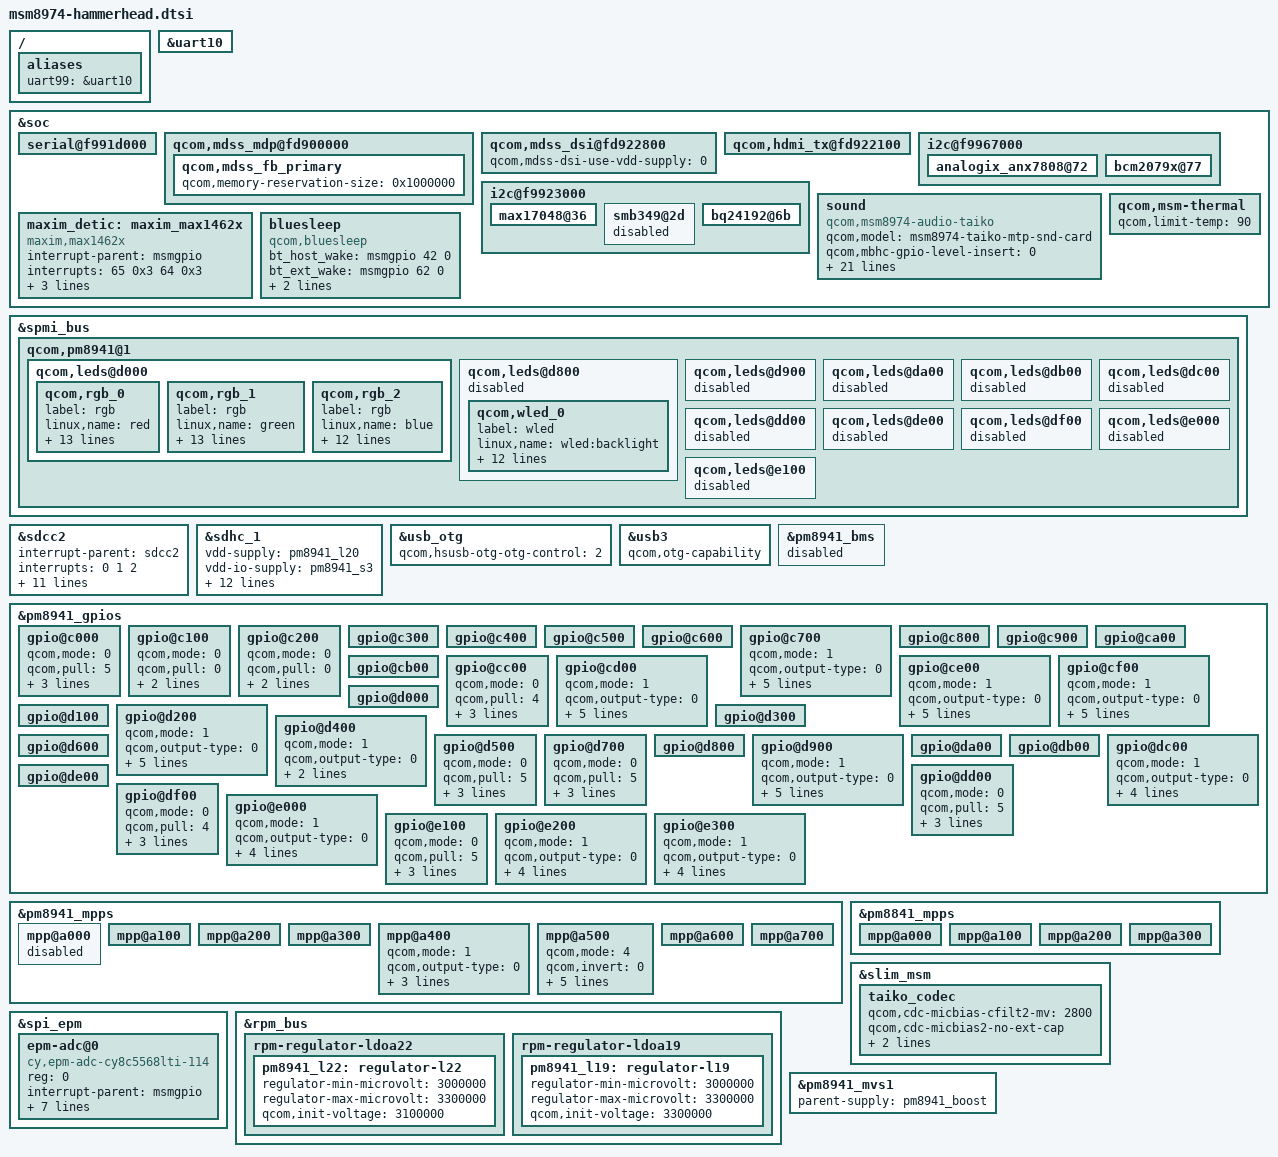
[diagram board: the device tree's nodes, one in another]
/* Copyright (c) 2012, Code Aurora Forum. All rights reserved.
 *
 * This program is free software; you can redistribute it and/or modify
 * it under the terms of the GNU General Public License version 2 and
 * only version 2 as published by the Free Software Foundation.
 *
 * This program is distributed in the hope that it will be useful,
 * but WITHOUT ANY WARRANTY; without even the implied warranty of
 * MERCHANTABILITY or FITNESS FOR A PARTICULAR PURPOSE.  See the
 * GNU General Public License for more details.
 */

/include/ "msm8974-hammerhead-panel.dtsi"
/include/ "msm8974-hammerhead-input.dtsi"
/include/ "msm8974-hammerhead-hdmi.dtsi"
/include/ "msm8974-hammerhead-usb.dtsi"
/include/ "msm8974-hammerhead-misc.dtsi"
/include/ "msm8974-hammerhead-pm.dtsi"
/include/ "msm8974-hammerhead-camera.dtsi"
/include/ "msm8974-hammerhead-nfc.dtsi"
/include/ "msm8974-hammerhead-regulator.dtsi"
/include/ "msm8974-hammerhead-sensor.dtsi"

/ {
	aliases {
		uart99 = &uart10;
	};
};

&uart10 {
	status = "ok";
};

&soc {
	serial@f991d000 {
		status = "ok";
	};

	qcom,mdss_mdp@fd900000 {
		qcom,mdss_fb_primary {
			qcom,memory-reservation-size = <0x1000000>;
		};
	};

	qcom,mdss_dsi@fd922800 {
		qcom,mdss-dsi-use-vdd-supply = <0>;
	};

	qcom,hdmi_tx@fd922100 {
		status = "ok";
	};

	i2c@f9967000 {
		analogix_anx7808@72 {
			status = "ok";
		};
	};
/* BLSP#1 is connected to I2c device, Gauge IC.
	spi@f9923000 {
		ethernet-switch@2 {
			compatible = "micrel,ks8851";
			reg = <2>;
			interrupt-parent = <&msmgpio>;
			interrupts = <94 0>;
			spi-max-frequency = <4800000>;
			rst-gpio = <&pm8941_mpps 6 0>;
			vdd-io-supply = <&spi_eth_vreg>;
			vdd-phy-supply = <&spi_eth_vreg>;
		};
	};
*/

	i2c@f9923000 {
		max17048@36 {
			status =  "ok";
		};

		smb349@2d {
			status = "disabled";
		};

		bq24192@6b {
			status = "ok";
		};
	};

	sound {
		compatible = "qcom,msm8974-audio-taiko";
		qcom,model = "msm8974-taiko-mtp-snd-card";
		qcom,mbhc-gpio-level-insert = <0>;

		qcom,mbhc-disabled = <1>;

		qcom,hdmi-audio-rx;

		qcom,audio-routing =
			"RX_BIAS", "MCLK",
			"LDO_H", "MCLK",
			"AIF4 MAD", "MCLK",
			"AMIC1", "MIC BIAS1 External",
			"MIC BIAS1 External", "Handset Mic",
			"AMIC2", "MIC BIAS2 External",
			"MIC BIAS2 External", "Headset Mic",
			"AMIC3", "MIC BIAS3 External",
			"MIC BIAS3 External", "Handset SubMic",
			"DMIC1", "MIC BIAS1 External",
			"MIC BIAS1 External", "Digital Mic1",
			"DMIC2", "MIC BIAS1 External",
			"MIC BIAS1 External", "Digital Mic2",
			"DMIC3", "MIC BIAS3 External",
			"MIC BIAS3 External", "Digital Mic3",
			"DMIC4", "MIC BIAS3 External",
			"MIC BIAS3 External", "Digital Mic4",
			"DMIC5", "MIC BIAS4 External",
			"MIC BIAS4 External", "Digital Mic5",
			"DMIC6", "MIC BIAS4 External",
			"MIC BIAS4 External", "Digital Mic6";

		qcom,cdc-mclk-gpios = <&pm8941_gpios 15 0>;
		taiko-mclk-clk = <&pm8941_clkdiv1>;
		qcom,taiko-mclk-clk-freq = <9600000>;
	};

	maxim_detic:maxim_max1462x {
		compatible = "maxim,max1462x";
		status = "ok";
		interrupt-parent = <&msmgpio>;
		interrupts = <65 0x3 64 0x3>;
		max1462x,gpio_detect = <&msmgpio 65 0x00>;
		max1462x,gpio_mic_en = <&pm8941_gpios 29 0x00>;
		max1462x,gpio_key = <&msmgpio 64 0x00>;
	};

	i2c@f9967000 {
		bcm2079x@77 {
			status = "ok";
		};
	};

	qcom,msm-thermal {
		qcom,limit-temp = <90>;
	};

	bluesleep {
		compatible = "qcom,bluesleep";
		bt_host_wake = <&msmgpio 42 0>;
		bt_ext_wake = <&msmgpio 62 0>;
		interrupt-parent = <&msmgpio>;
		interrupts = <42 0>;
		interrupt-names = "host_wake";
	};
};

&spmi_bus {
	qcom,pm8941@1 {
		qcom,leds@d000 {
			status = "okay";
			qcom,rgb_0 {
				label = "rgb";
				linux,name = "red";
				qcom,mode = "lpg";
				qcom,pwm-channel = <6>;
				qcom,pwm-us = <200>;
				qcom,duty-ms = <70>;
				qcom,start-idx = <0>;
				qcom,idx-len = <63>;
				qcom,duty-pcts = [
					 00 09 09 00 00
					 00 00 00 15 2A
					 3F 2A 15 00 00
					 00 00 00 00 00
					 00 00 2C 57 5E
					 64 63 63 63 62
					 60 5F 5D 5A 58
					 53 4F 4A 41 37
					 2D 17 00 00 00
					 22 43 2C 16 00
					 00 00 00 00 00
					 09 10 21 31 21
					 10 09 00
					 ];
				qcom,max-current = <12>;
				qcom,default-state = "off";
				qcom,id = <3>;
				linux,default-trigger = "none";
				qcom,calibrated-max = <111>;
			};

			qcom,rgb_1 {
				label = "rgb";
				linux,name = "green";
				qcom,mode = "lpg";
				qcom,pwm-channel = <5>;
				qcom,pwm-us = <200>;
				qcom,duty-ms = <70>;
				qcom,start-idx = <0>;
				qcom,idx-len = <63>;
				qcom,duty-pcts = [
					 00 09 09 00 00
					 00 00 00 15 2A
					 3F 2A 15 00 00
					 00 00 00 00 00
					 00 00 2C 57 5E
					 64 63 63 63 62
					 60 5F 5D 5A 58
					 53 4F 4A 41 37
					 2D 17 00 00 00
					 22 43 2C 16 00
					 00 00 00 00 00
					 09 10 21 31 21
					 10 09 00
					 ];
				qcom,max-current = <12>;
				qcom,default-state = "off";
				qcom,id = <4>;
				linux,default-trigger = "none";
				qcom,calibrated-max = <239>;
			};

			qcom,rgb_2 {
				label = "rgb";
				linux,name = "blue";
				qcom,mode = "lpg";
				qcom,pwm-channel = <4>;
				qcom,pwm-us = <200>;
				qcom,duty-ms = <70>;
				qcom,start-idx = <0>;
				qcom,idx-len = <63>;
				qcom,duty-pcts = [
					 00 09 09 00 00
					 00 00 00 15 2A
					 3F 2A 15 00 00
					 00 00 00 00 00
					 00 00 2C 57 5E
					 64 63 63 63 62
					 60 5F 5D 5A 58
					 53 4F 4A 41 37
					 2D 17 00 00 00
					 22 43 2C 16 00
					 00 00 00 00 00
					 09 10 21 31 21
					 10 09 00
					 ];
				qcom,max-current = <12>;
				qcom,default-state = "off";
				qcom,id = <5>;
				linux,default-trigger = "none";
			};
		};

		qcom,leds@d800 {
			status = "disable";
			qcom,wled_0 {
				label = "wled";
				linux,name = "wled:backlight";
				linux,default-trigger = "bkl-trigger";
				qcom,cs-out-en;
				qcom,op-fdbck;
				qcom,default-state = "off";
				qcom,max-current = <25>;
				qcom,ctrl-delay-us = <0>;
				qcom,boost-curr-lim = <3>;
				qcom,cp-sel = <0>;
				qcom,switch-freq = <2>;
				qcom,ovp-val = <2>;
				qcom,num-strings = <1>;
				qcom,id = <0>;
			};
		};

		qcom,leds@d900 {
			status = "disabled";
		};

		qcom,leds@da00 {
			status = "disabled";
		};

		qcom,leds@db00 {
			status = "disabled";
		};

		qcom,leds@dc00 {
			status = "disabled";
		};

		qcom,leds@dd00 {
			status = "disabled";
		};

		qcom,leds@de00 {
			status = "disabled";
		};

		qcom,leds@df00 {
			status = "disabled";
		};

		qcom,leds@e000 {
			status = "disabled";
		};

		qcom,leds@e100 {
			status = "disabled";
		};
	};
};

&sdcc2 {
	#address-cells = <0>;
	interrupt-parent = <&sdcc2>;
	interrupts = <0 1 2>;
	#interrupt-cells = <1>;
	interrupt-map-mask = <0xffffffff>;

	/* Qualcomm / Broadcom WiFi solution definition.
	 * You must choose one solution
	 */

	/* Qualcomm WiFi solution - Start */
	/*
	interrupt-map = <0 &intc 0 125 0
		1 &intc 0 220 0
		2 &msmgpio 35 0x3>;
	interrupt-names = "core_irq", "bam_irq", "wlan_oob_irq";
	qcom,bus-width = <4>;

	vdd-supply = <&pm8941_l11>;
	qcom,sdcc-sup-voltages = <1800 2950>;
	qcom,sdcc-nonremovable = <1>;
	qcom,sup-voltages = <1800 2950>;
	qcom,nonremovable;
	*/
	/* Qualcomm WiFi solution - End */

	/* Broadcom WiFi solution - Start */
	interrupt-map = <0 &intc 0 125 0
		1 &intc 0 220 0
		2 &msmgpio 44 0x3>;
	interrupt-names = "core_irq", "bam_irq", "wlan_oob_irq";
	qcom,bus-width = <4>;

	qcom,sdcc-sup-voltages = <1800 2950>;
	qcom,sup-voltages = <1800 2950>;
	qcom,wifi-control-func;
	qcom,not-use-vdd;
	vdd-io-supply = <&pm8941_s3>;
	/* Broadcom WiFi solution - End */

	qcom,vdd-io-voltage-level = <1800000 1800000>;
	qcom,vdd-io-current-level = <6 22000>;
	status = "ok";
};

&sdhc_1 {
	vdd-supply = <&pm8941_l20>;
	vdd-io-supply = <&pm8941_s3>;

	qcom,vdd-always-on;
	qcom,vdd-lpm-sup;
	qcom,vdd-voltage-level = <2950000 2950000>;
	qcom,vdd-current-level = <800 500000>;

	qcom,vdd-io-always-on;
	qcom,vdd-io-voltage-level = <1800000 1800000>;
	qcom,vdd-io-current-level = <250 154000>;

	qcom,pad-pull-on = <0x0 0x3 0x3>; /* no-pull, pull-up, pull-up */
	qcom,pad-pull-off = <0x0 0x3 0x3>; /* no-pull, pull-up, pull-up */
	qcom,pad-drv-on = <0x1 0x1 0x1>; /* 4mA, 4mA, 4mA */
	qcom,pad-drv-off = <0x0 0x0 0x0>; /* 2mA, 2mA, 2mA */

	qcom,nonremovable;
	status = "ok";
};

&usb_otg {
	qcom,hsusb-otg-otg-control = <2>;
};

&usb3 {
	qcom,otg-capability;
};

&pm8941_bms {
	status = "disable";
};

&pm8941_gpios {
	gpio@c000 { /* GPIO 1 */
		status = "ok";			/* HPH_AUD_SW_INT */
		qcom,mode = <0>;		/* QPNP_PIN_MODE_DIG_IN */
		qcom,pull = <5>;		/* QPNP_PIN_PULL_NO */
		qcom,vin-sel = <2>;		/* QPNP_PIN_VIN1 */
		qcom,src-sel = <0>;		/* QPNP_PIN_SEL_FUNC_CONSTANT */
		qcom,master-en = <1>;
	};

	gpio@c100 { /* GPIO 2 */
		status = "ok";			/* KEY_UP */
		qcom,mode = <0>;		/* QPNP_PIN_MODE_DIG_IN */
		qcom,pull = <0>;		/* QPNP_PIN_PULL_UP_30 */
		qcom,vin-sel = <2>;		/* QPNP_PIN_VIN2 */
		qcom,src-sel = <0>;		/* QPNP_PIN_SEL_FUNC_CONSTANT */
	};

	gpio@c200 { /* GPIO 3 */
		status = "ok";			/* KEY_DOWN */
		qcom,mode = <0>;		/* QPNP_PIN_MODE_DIG_IN */
		qcom,pull = <0>;		/* QPNP_PIN_PULL_UP_30 */
		qcom,vin-sel = <2>;		/* QPNP_PIN_VIN2 */
		qcom,src-sel = <0>;		/* QPNP_PIN_SEL_FUNC_CONSTANT */
	};

	gpio@c300 { /* GPIO 4 */
	};

	gpio@c400 { /* GPIO 5 */
	};

	gpio@c500 { /* GPIO 6 */
	};

	gpio@c600 { /* GPIO 7 */
	};

	gpio@c700 { /* GPIO 8 */
		status = "ok";			/* SLIMPORT_IOVCC_EN */
		qcom,mode = <1>;		/* QPNP_PIN_MODE_DIG_OUT */
		qcom,output-type = <0>;		/* QPNP_PIN_OUT_BUF_CMOS */
		qcom,pull = <5>;		/* QPNP_PIN_PULL_NO */
		qcom,vin-sel = <2>;		/* QPNP_PIN_VIN2 */
		qcom,out-strength = <2>;	/* QPNP_PIN_OUT_STRENGTH_MED */
		qcom,src-sel = <0>;		/* QPNP_PIN_SEL_FUNC_CONSTANT */
		qcom,master-en = <1>;
	};

	gpio@c800 { /* GPIO 9 */
	};

	gpio@c900 { /* GPIO 10 */
	};

	gpio@ca00 { /* GPIO 11 */
	};

	gpio@cb00 { /* GPIO 12 */
	};

	gpio@cc00 { /* GPIO 13 */
		status = "ok";			/* SLIMPORT_CBL_DET */
		qcom,mode = <0>;		/* QPNP_PIN_MODE_DIG_IN */
		qcom,pull = <4>;		/* QPNP_PIN_PULL_DN */
		qcom,vin-sel = <2>;		/* QPNP_PIN_VIN2 */
		qcom,src-sel = <0>;		/* QPNP_PIN_SEL_FUNC_CONSTANT */
		qcom,master-en = <1>;
	};

	gpio@cd00 { /* GPIO 14 */
		status = "ok";			/* ANX_P_DWN_CTL */
		qcom,mode = <1>;		/* QPNP_PIN_MODE_DIG_OUT */
		qcom,output-type = <0>;		/* QPNP_PIN_OUT_BUF_CMOS */
		qcom,pull = <5>;		/* QPNP_PIN_PULL_NO */
		qcom,vin-sel = <2>;		/* QPNP_PIN_VIN2 */
		qcom,out-strength = <2>;	/* QPNP_PIN_OUT_STRENGTH_MED */
		qcom,src-sel = <0>;		/* QPNP_PIN_SEL_FUNC_CONSTANT */
		qcom,master-en = <1>;
	};

	gpio@ce00 { /* GPIO 15 */
		status = "ok";			/* WCD_MCLK */
		qcom,mode = <1>;		/* QPNP_PIN_MODE_DIG_OUT */
		qcom,output-type = <0>;		/* QPNP_PIN_OUT_BUF_CMOS */
		qcom,pull = <5>;		/* QPNP_PIN_PULL_NO */
		qcom,vin-sel = <2>;		/* QPNP_PIN_VIN2 */
		qcom,out-strength = <3>;	/* QPNP_PIN_OUT_STRENGTH_MED */
		qcom,src-sel = <2>;		/* QPNP_PIN_SEL_FUNC_1 */
		qcom,master-en = <1>;
	};

	gpio@cf00 { /* GPIO 16 */
		status = "ok";			/* SLEEP_CLK_BCM */
		qcom,mode = <1>;		/* QPNP_PIN_MODE_DIG_OUT */
		qcom,output-type = <0>;		/* QPNP_PIN_OUT_BUF_CMOS */
		qcom,pull = <5>;		/* QPNP_PIN_PULL_NO */
		qcom,vin-sel = <2>;		/* QPNP_PIN_VIN2 */
		qcom,out-strength = <3>;	/* QPNP_PIN_OUT_STRENGTH_MED */
		qcom,src-sel = <3>;		/* QPNP_PIN_SEL_FUNC_2 */
		qcom,master-en = <1>;
	};

	gpio@d000 { /* GPIO 17 */
	};

	gpio@d100 { /* GPIO 18 */
	};

	gpio@d200 { /* GPIO 19 */
		status = "ok";			/* LCD_RESET_N */
		qcom,mode = <1>;		/* QPNP_PIN_MODE_DIG_OUT */
		qcom,output-type = <0>;		/* QPNP_PIN_OUT_BUF_CMOS */
		qcom,pull = <5>;		/* QPNP_PIN_PULL_NO */
		qcom,vin-sel = <2>;		/* QPNP_PIN_VIN2 */
		qcom,out-strength = <2>;	/* QPNP_PIN_OUT_STRENGTH_MED */
		qcom,src-sel = <0>;		/* QPNP_PIN_SEL_FUNC_CONSTANT */
		qcom,master-en = <1>;
	};

	gpio@d300 { /* GPIO 20 */
	};

	gpio@d400 { /* GPIO 21 */
		status = "ok";
		qcom,mode = <1>;
		qcom,output-type = <0>;
		qcom,pull = <4>;
		qcom,src-sel = <0>;
	};

	gpio@d500 { /* GPIO 22 */
		status = "ok";			/* CHG_INT */
		qcom,mode = <0>;		/* QPNP_PIN_MODE_DIG_IN */
		qcom,pull = <5>;		/* QPNP_PIN_PULL_NO */
		qcom,vin-sel = <2>;		/* QPNP_PIN_VIN2 */
		qcom,src-sel = <0>;		/* QPNP_PIN_SEL_FUNC_CONSTANT */
		qcom,master-en = <1>;
	};

	gpio@d600 { /* GPIO 23 */
	};

	gpio@d700 { /* GPIO 24 */
		status = "ok";			/* CHARGER_PG */
		qcom,mode = <0>;		/* QPNP_PIN_MODE_DIG_IN */
		qcom,pull = <5>;		/* QPNP_PIN_PULL_NO */
		qcom,vin-sel = <2>;		/* QPNP_PIN_VIN2 */
		qcom,src-sel = <0>;		/* QPNP_PIN_SEL_FUNC_CONSTANT */
		qcom,master-en = <1>;
	};

	gpio@d800 { /* GPIO 25 */
	};

	gpio@d900 { /* GPIO 26 */
		status = "ok";			/* SLIMPORT_AVDD33_EN */
		qcom,mode = <1>;		/* QPNP_PIN_MODE_DIG_OUT */
		qcom,output-type = <0>;		/* QPNP_PIN_OUT_BUF_CMOS */
		qcom,pull = <5>;		/* QPNP_PIN_PULL_NO */
		qcom,vin-sel = <2>;		/* QPNP_PIN_VIN2 */
		qcom,out-strength = <2>;	/* QPNP_PIN_OUT_STRENGTH_MED */
		qcom,src-sel = <0>;		/* QPNP_PIN_SEL_FUNC_CONSTANT */
		qcom,master-en = <1>;
	};

	gpio@da00 { /* GPIO 27 */
	};

	gpio@db00 { /* GPIO 28 */
	};

	gpio@dc00 { /* GPIO 29 */
		status = "ok";			/* EAR_MIC_EN */
		qcom,mode = <1>;		/* QPNP_PIN_MODE_DIG_OUT */
		qcom,output-type = <0>;		/* QPNP_PIN_OUT_BUF_CMOS */
		qcom,pull = <0>;		/* QPNP_PIN_PULL_UP_30 */
		qcom,vin-sel = <2>;		/* QPNP_PIN_VIN2 */
		qcom,src-sel = <0>;		/* QPNP_PIN_SEL_FUNC_CONSTANT */
		qcom,master-en = <1>;
	};

	gpio@dd00 { /* GPIO 30 */
		status = "ok";			/* EXT_CHG_STAT */
		qcom,mode = <0>;		/* QPNP_PIN_MODE_DIG_IN */
		qcom,pull = <5>;		/* QPNP_PIN_PULL_NO */
		qcom,vin-sel = <2>;		/* QPNP_PIN_VIN2 */
		qcom,src-sel = <0>;		/* QPNP_PIN_SEL_FUNC_CONSTANT */
		qcom,master-en = <1>;
	};

	gpio@de00 { /* GPIO 31 */
	};

	gpio@df00 { /* GPIO 32 */
		status = "ok";
		qcom,mode = <0>;		/* QPNP_PIN_MODE_DIG_IN */
		qcom,pull = <4>;		/* QPNP_PIN_PULL_DOWN */
		qcom,src-sel = <2>;		/* QPNP_PIN_SEL_FUNC_1 */
		qcom,vin-sel = <2>;		/* Select 1.8V Source */
		qcom,master-en = <1>;		/* Enable Module */
	};

	gpio@e000 { /* GPIO 33 */
		status = "ok";			/* CHG_EN */
		qcom,mode = <1>;		/* QPNP_PIN_MODE_DIG_OUT */
		qcom,output-type = <0>;		/* QPNP_PIN_OUT_BUF_CMOS */
		qcom,pull = <5>;		/* QPNP_PIN_PULL_NO */
		qcom,vin-sel = <2>;		/* QPNP_PIN_VIN2 */
		qcom,src-sel = <0>;		/* QPNP_PIN_SEL_FUNC_CONSTANT */
		qcom,master-en = <1>;
	};

	gpio@e100 { /* GPIO 34 */
		status = "ok";			/* WLC_INT */
		qcom,mode = <0>;		/* QPNP_PIN_MODE_DIG_IN */
		qcom,pull = <5>;		/* QPNP_PIN_PULL_NO */
		qcom,vin-sel = <2>;		/* QPNP_PIN_VIN2 */
		qcom,src-sel = <0>;		/* QPNP_PIN_SEL_FUNC_CONSTANT */
		qcom,master-en = <1>;
	};

	gpio@e200 { /* GPIO 35 */
		status = "ok";			/* OTG_EN */
		qcom,mode = <1>;		/* QPNP_PIN_MODE_DIG_OUT */
		qcom,output-type = <0>;		/* QPNP_PIN_OUT_BUF_CMOS */
		qcom,pull = <5>;		/* QPNP_PIN_PULL_NO */
		qcom,vin-sel = <2>;		/* QPNP_PIN_VIN2 */
		qcom,src-sel = <0>;		/* QPNP_PIN_SEL_FUNC_CONSTANT */
		qcom,master-en = <1>;
	};

	gpio@e300 { /* GPIO 36 */
		status = "ok";			/* WLC_FULL_CHG */
		qcom,mode = <1>;		/* QPNP_PIN_MODE_DIG_OUT */
		qcom,output-type = <0>;		/* QPNP_PIN_OUT_BUF_CMOS */
		qcom,pull = <4>;		/* QPNP_PIN_PULL_DN */
		qcom,vin-sel = <2>;		/* QPNP_PIN_VIN2 */
		qcom,src-sel = <0>;		/* QPNP_PIN_SEL_FUNC_CONSTANT */
		qcom,master-en = <1>;
	};
};

&pm8941_mpps {

	mpp@a000 { /* MPP 1 */
		status = "disabled";
	};

	mpp@a100 { /* MPP 2 */
	};

	mpp@a200 { /* MPP 3 */
	};

	mpp@a300 { /* MPP 4 */
	};

	mpp@a400 { /* MPP 5 */
		/* SPI_ETH config */
		qcom,mode = <1>; /* DIG_OUT */
		qcom,output-type = <0>; /* CMOS */
		qcom,vin-sel = <2>; /* PM8941_S3 1.8V > 1.6V */
		qcom,src-sel = <0>; /* CONSTANT */
		qcom,master-en = <1>; /* ENABLE MPP */
	};

	mpp@a500 { /* MPP 6 */
		/* Maxim Headset Detection */
		qcom,mode = <4>; /* QPNP_PIN_MODE_AIN */
		qcom,invert = <0>; /*no invert*/
		qcom,output-type = <0>; /* CMOS */
		qcom,vin-sel = <2>; /* PM8941_S3 1.8V > 1.6V */
		qcom,src-sel = <0>; /* CONSTANT */
		qcom,ain-route = <1>;
		qcom,master-en = <1>;
	};

	mpp@a600 { /* MPP 7 */
	};

	mpp@a700 { /* MPP 8 */
	};
};

&pm8841_mpps {

	mpp@a000 { /* MPP 1 */
	};

	mpp@a100 { /* MPP 2 */
	};

	mpp@a200 { /* MPP 3 */
	};

	mpp@a300 { /* MPP 4 */
	};
};

&slim_msm {
	taiko_codec {
		qcom,cdc-micbias-cfilt2-mv = <2800>;
		qcom,cdc-micbias2-no-ext-cap;
		qcom,cdc-micbias3-cfilt-sel = <0x0>;
		qcom,cdc-micbias4-cfilt-sel = <0x0>;
	};
};

&spi_epm {
	epm-adc@0 {
		compatible = "cy,epm-adc-cy8c5568lti-114";
		reg = <0>;
		interrupt-parent = <&msmgpio>;
		spi-max-frequency = <960000>;
		qcom,channels = <31>;
		qcom,gain = <100 100 100 50 100 100 1 100 1 50
			1 100 1 100 50 50 50 50 50 50
			100 50 100 50 50 50 50 50 50 50
			50>;
		qcom,rsense = <2 2 2 200 20 2 1 2 1 30
			1 10 1 30 50 30 500 30 100 30
			100 500 20 200 1000 20 1000 1000 70 200
			50>;
		qcom,channel-type = <0x1540>;
	};
};

&rpm_bus {
	rpm-regulator-ldoa22 {
		pm8941_l22: regulator-l22 {
			regulator-min-microvolt = <3000000>;
			regulator-max-microvolt = <3300000>;
			qcom,init-voltage = <3100000>;
		};
	};

	rpm-regulator-ldoa19 {
		pm8941_l19: regulator-l19 {
			regulator-min-microvolt = <3000000>;
			regulator-max-microvolt = <3300000>;
			qcom,init-voltage = <3300000>;
		};
	};
};

&pm8941_mvs1 {
	parent-supply = <&pm8941_boost>;
};
